# STM32U545 register map
File version: 1.7
CPU: CM33 r0p1, little endian, MPU, FPU, 4 interrupt priority bits
Registers are 32-bit, read-write, reset 0x0 unless marked. A register's access mark holds for its fields unless they carry their own. Offsets are from the block's base; [hi:lo] are bit positions; {n}, {i} and the like mark numbered series.

## GTZC1_TZIC
Base 0x40032800
Same registers: SEC_GTZC1_TZIC 0x50032800
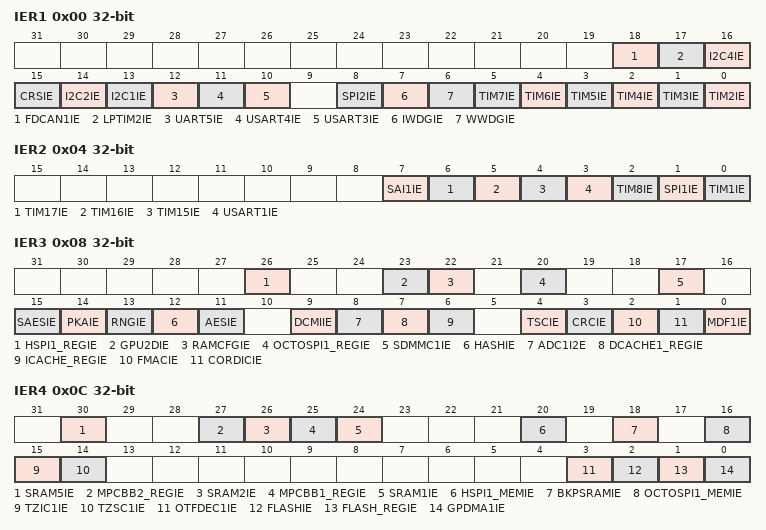
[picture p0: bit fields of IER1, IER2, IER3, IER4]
0x00 IER1 — TZIC interrupt enable register 1
  [18] FDCAN1IE — illegal access interrupt enable for FDCAN1
  [17] LPTIM2IE — illegal access interrupt enable for LPTIM2
  [16] I2C4IE — illegal access interrupt enable for I2C4
  [15] CRSIE — illegal access interrupt enable for CRS
  [14] I2C2IE — illegal access interrupt enable for I2C2
  [13] I2C1IE — illegal access interrupt enable for I2C1
  [12] UART5IE — illegal access interrupt enable for UART5
  [11] USART4IE — illegal access interrupt enable for UART4
  [10] USART3IE — illegal access interrupt enable for USART3
  [8] SPI2IE
  [7] IWDGIE
  [6] WWDGIE
  [n-2] TIM{n}IE (n=2..7)
0x04 IER2 — TZIC interrupt enable register 2
  [7] SAI1IE — illegal access interrupt enable for SAI1
  [6] TIM17IE — illegal access interrupt enable for TIM7
  [5] TIM16IE — illegal access interrupt enable for TIM6
  [4] TIM15IE — illegal access interrupt enable for TIM5
  [3] USART1IE — illegal access interrupt enable for USART1
  [2] TIM8IE — illegal access interrupt enable for TIM8
  [1] SPI1IE — illegal access interrupt enable for SPI1
  [0] TIM1IE — illegal access interrupt enable for TIM1
0x08 IER3 — TZIC interrupt enable register 3
  [26] HSPI1_REGIE
  [23] GPU2DIE
  [22] RAMCFGIE — illegal access interrupt enable for RAMCFG
  [20] OCTOSPI1_REGIE — illegal access interrupt enable for OCTOSPI1 registers
  [17] SDMMC1IE — illegal access interrupt enable
  [15] SAESIE — illegal access interrupt enable for SAES
  [14] PKAIE — illegal access interrupt enable for PKA
  [13] RNGIE — illegal access interrupt enable for RNG
  [12] HASHIE — illegal access interrupt enable for HASH
  [11] AESIE — illegal access interrupt enable for AES
  [9] DCMIIE — illegal access interrupt enable for DCMI
  [8] ADC1I2E — illegal access interrupt enable for ADC1 or ADC2
  [7] DCACHE1_REGIE — illegal access interrupt enable for DCACHE registers
  [6] ICACHE_REGIE — illegal access interrupt enable for ICACHE registers
  [4] TSCIE — illegal access interrupt enable for TSC
  [3] CRCIE — illegal access interrupt enable for CRC
  [2] FMACIE — illegal access interrupt enable for FMAC
  [1] CORDICIE — illegal access interrupt enable for CORDIC
  [0] MDF1IE — illegal access interrupt enable for MDF1
0x0C IER4 — TZIC interrupt enable register 4
  [30] SRAM5IE — illegal access interrupt enable for SRAM5
  [27] MPCBB2_REGIE — illegal access interrupt enable for MPCBB2 registers
  [26] SRAM2IE — illegal access interrupt enable for SRAM2
  [25] MPCBB1_REGIE — illegal access interrupt enable for MPCBB1 registers
  [24] SRAM1IE — illegal access interrupt enable for SRAM1
  [20] HSPI1_MEMIE — illegal access interrupt enable for HSPI1 memory bank
  [18] BKPSRAMIE — illegal access interrupt enable for MPCWM3 (BKPSRAM) memory bank
  [16] OCTOSPI1_MEMIE — illegal access interrupt enable for MPCWM1 (OCTOSPI1) memory bank
  [15] TZIC1IE — illegal access interrupt enable for GTZC1 TZIC registers
  [14] TZSC1IE — illegal access interrupt enable for GTZC1 TZSC registers
  [3] OTFDEC1IE — illegal access interrupt enable for OTFDEC1
  [2] FLASHIE — illegal access interrupt enable for FLASH memory
  [1] FLASH_REGIE — illegal access interrupt enable for FLASH registers
  [0] GPDMA1IE — illegal access interrupt enable for GPDMA1
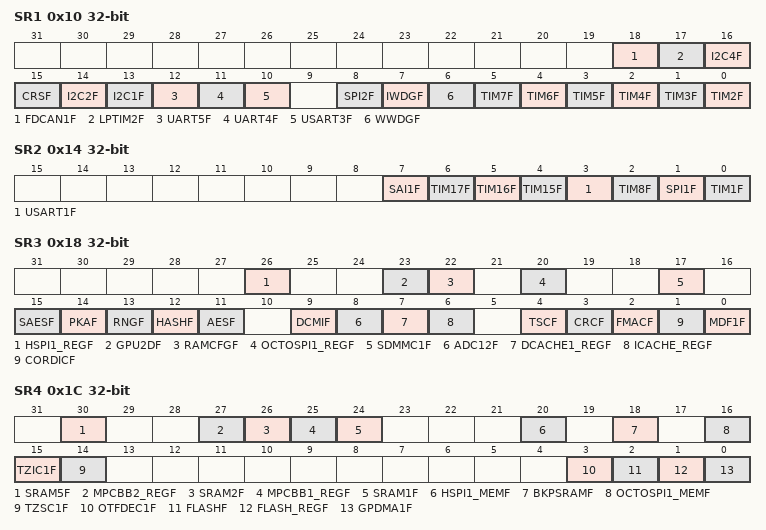
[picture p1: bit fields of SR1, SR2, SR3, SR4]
0x10 SR1 ro — TZIC status register 1
  [18] FDCAN1F — illegal access flag for FDCAN1
  [17] LPTIM2F — illegal access flag for LPTIM2
  [16] I2C4F — illegal access flag for I2C4
  [15] CRSF — illegal access flag for CRS
  [14] I2C2F — illegal access flag for I2C2
  [13] I2C1F — illegal access flag for I2C1
  [12] UART5F — illegal access flag for UART5
  [11] UART4F — illegal access flag for UART4
  [10] USART3F — illegal access flag for USART3
  [8] SPI2F — illegal access flag for SPI2
  [7] IWDGF — illegal access flag for IWDG
  [6] WWDGF — illegal access flag for WWDG
  [n-2] TIM{n}F (n=2..7) — illegal access flag for TIM{n}
0x14 SR2 ro — TZIC status register 2
  [7] SAI1F — illegal access flag for SAI1
  [6] TIM17F — illegal access flag for TIM7
  [5] TIM16F — illegal access flag for TIM6
  [4] TIM15F — illegal access flag for TIM5
  [3] USART1F — illegal access flag for USART1
  [2] TIM8F — illegal access flag for TIM8
  [1] SPI1F — illegal access flag for SPI1
  [0] TIM1F — illegal access flag for TIM1
0x18 SR3 ro — TZIC status register 3
  [26] HSPI1_REGF — illegal access flag for HSPI1 registers
  [23] GPU2DF — illegal access flag for GPU2D
  [22] RAMCFGF — illegal access flag for RAMCFG
  [20] OCTOSPI1_REGF — illegal access flag for OCTOSPI1 registers
  [17] SDMMC1F — illegal access flag
  [15] SAESF — illegal access flag for SAES
  [14] PKAF — illegal access flag for PKA
  [13] RNGF — illegal access flag for RNG
  [12] HASHF — illegal access flag for HASH
  [11] AESF — illegal access flag for AES
  [9] DCMIF — illegal access flag for DCMI
  [8] ADC12F — illegal access flag for ADC1 and ADC2
  [7] DCACHE1_REGF — illegal access flag for DCACHE registers
  [6] ICACHE_REGF — illegal access flag for ICACHE registers
  [4] TSCF — illegal access flag for TSC
  [3] CRCF — illegal access flag for CRC
  [2] FMACF — illegal access flag for FMAC
  [1] CORDICF — illegal access flag for CORDIC
  [0] MDF1F — illegal access flag for MDF1
0x1C SR4 ro — TZIC status register 4
  [30] SRAM5F — illegal access flag for SRAM5
  [27] MPCBB2_REGF — illegal access flag for MPCBB2 registers
  [26] SRAM2F — illegal access flag for SRAM2
  [25] MPCBB1_REGF — illegal access flag for MPCBB1 registers
  [24] SRAM1F — illegal access flag for SRAM1
  [20] HSPI1_MEMF — illegal access flag for HSPI1 memory bank
  [18] BKPSRAMF — illegal access flag for MPCWM3 (BKPSRAM) memory bank
  [16] OCTOSPI1_MEMF — illegal access flag for MPCWM1 (OCTOSPI1) memory bank
  [15] TZIC1F — illegal access flag for GTZC1 TZIC registers
  [14] TZSC1F — illegal access flag for GTZC1 TZSC registers
  [3] OTFDEC1F — illegal access flag for OTFDEC1
  [2] FLASHF — illegal access flag for FLASH memory
  [1] FLASH_REGF — illegal access flag for FLASH registers
  [0] GPDMA1F — illegal access flag for GPDMA1
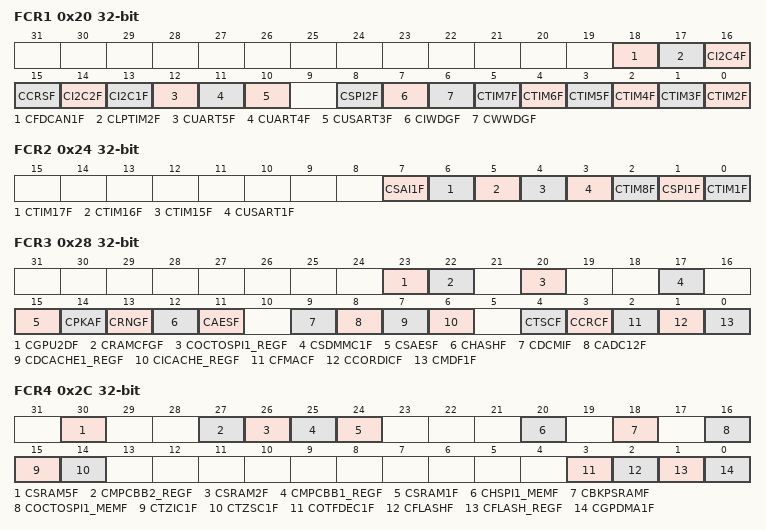
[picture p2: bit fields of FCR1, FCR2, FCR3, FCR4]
0x20 FCR1 wo — TZIC flag clear register 1
  [18] CFDCAN1F — clear the illegal access flag for FDCAN1
  [17] CLPTIM2F — clear the illegal access flag for LPTIM2
  [16] CI2C4F — clear the illegal access flag for I2C4
  [15] CCRSF — clear the illegal access flag for CRS
  [14] CI2C2F — clear the illegal access flag for I2C2
  [13] CI2C1F — clear the illegal access flag for I2C1
  [12] CUART5F — clear the illegal access flag for UART5
  [11] CUART4F — clear the illegal access flag for UART4
  [10] CUSART3F — clear the illegal access flag for USART3
  [8] CSPI2F — clear the illegal access flag for SPI2
  [7] CIWDGF — clear the illegal access flag for IWDG
  [6] CWWDGF — clear the illegal access flag for WWDG
  [n-2] CTIM{n}F (n=2..7) — clear the illegal access flag for TIM{n}
0x24 FCR2 wo — TZIC flag clear register 2
  [7] CSAI1F — clear the illegal access flag for SAI1
  [6] CTIM17F — clear the illegal access flag for TIM7
  [5] CTIM16F — clear the illegal access flag for TIM6
  [4] CTIM15F — clear the illegal access flag for TIM5
  [3] CUSART1F — clear the illegal access flag for USART1
  [2] CTIM8F — clear the illegal access flag for TIM8
  [1] CSPI1F — clear the illegal access flag for SPI1
  [0] CTIM1F — clear the illegal access flag for TIM1
0x28 FCR3 wo — TZIC flag clear register 3
  [23] CGPU2DF — clear the illegal access flag for GPU2D
  [22] CRAMCFGF — clear the illegal access flag for RAMCFG
  [20] COCTOSPI1_REGF — clear the illegal access flag for OCTOSPI1 registers
  [17] CSDMMC1F — clear the illegal access flag
  [15] CSAESF — clear the illegal access flag for SAES
  [14] CPKAF — clear the illegal access flag for PKA
  [13] CRNGF — clear the illegal access flag for RNG
  [12] CHASHF — clear the illegal access flag for HASH
  [11] CAESF — clear the illegal access flag for AES
  [9] CDCMIF — clear the illegal access flag for DCMI
  [8] CADC12F — clear the illegal access flag for ADC1 and ADC2
  [7] CDCACHE1_REGF — clear the illegal access flag for DCACHE1 registers
  [6] CICACHE_REGF — clear the illegal access flag for ICACHE registers
  [4] CTSCF — clear the illegal access flag for TSC
  [3] CCRCF — clear the illegal access flag for CRC
  [2] CFMACF — clear the illegal access flag for FMAC
  [1] CCORDICF — clear the illegal access flag for CORDIC
  [0] CMDF1F — clear the illegal access flag for MDF1
0x2C FCR4 wo — TZIC flag clear register 4
  [30] CSRAM5F — clear the illegal access flag for SRAM5
  [27] CMPCBB2_REGF — clear the illegal access flag for MPCBB2 registers
  [26] CSRAM2F — clear the illegal access flag for SRAM2
  [25] CMPCBB1_REGF — clear the illegal access flag for MPCBB1 registers
  [24] CSRAM1F — clear the illegal access flag for SRAM1
  [20] CHSPI1_MEMF — clear the illegal access flag for HSPI1 memory bank
  [18] CBKPSRAMF — clear the illegal access flag for MPCWM3 (BKPSRAM) memory bank
  [16] COCTOSPI1_MEMF — clear the illegal access flag for MPCWM1 (OCTOSPI1) memory bank
  [15] CTZIC1F — clear the illegal access flag for GTZC1 TZIC registers
  [14] CTZSC1F — clear the illegal access flag for GTZC1 TZSC registers
  [3] COTFDEC1F — clear the illegal access flag for OTFDEC1
  [2] CFLASHF — clear the illegal access flag for FLASH memory
  [1] CFLASH_REGF — clear the illegal access flag for FLASH registers
  [0] CGPDMA1F — clear the illegal access flag for GPDMA1

## Notices in the file
Copyright (c) 2025 STMicroelectronics.
SPDX-License-Identifier: Apache-2.0
Licensed under the Apache License, Version 2.0 (the "License");
you may not use this file except in compliance with the License.
You may obtain a copy of the License at
http://www.apache.org/licenses/LICENSE-2.0
Unless required by applicable law or agreed to in writing, software
distributed under the License is distributed on an "AS IS" BASIS,
WITHOUT WARRANTIES OR CONDITIONS OF ANY KIND, either express or implied.
See the License for the specific language governing permissions and
limitations under the License.
